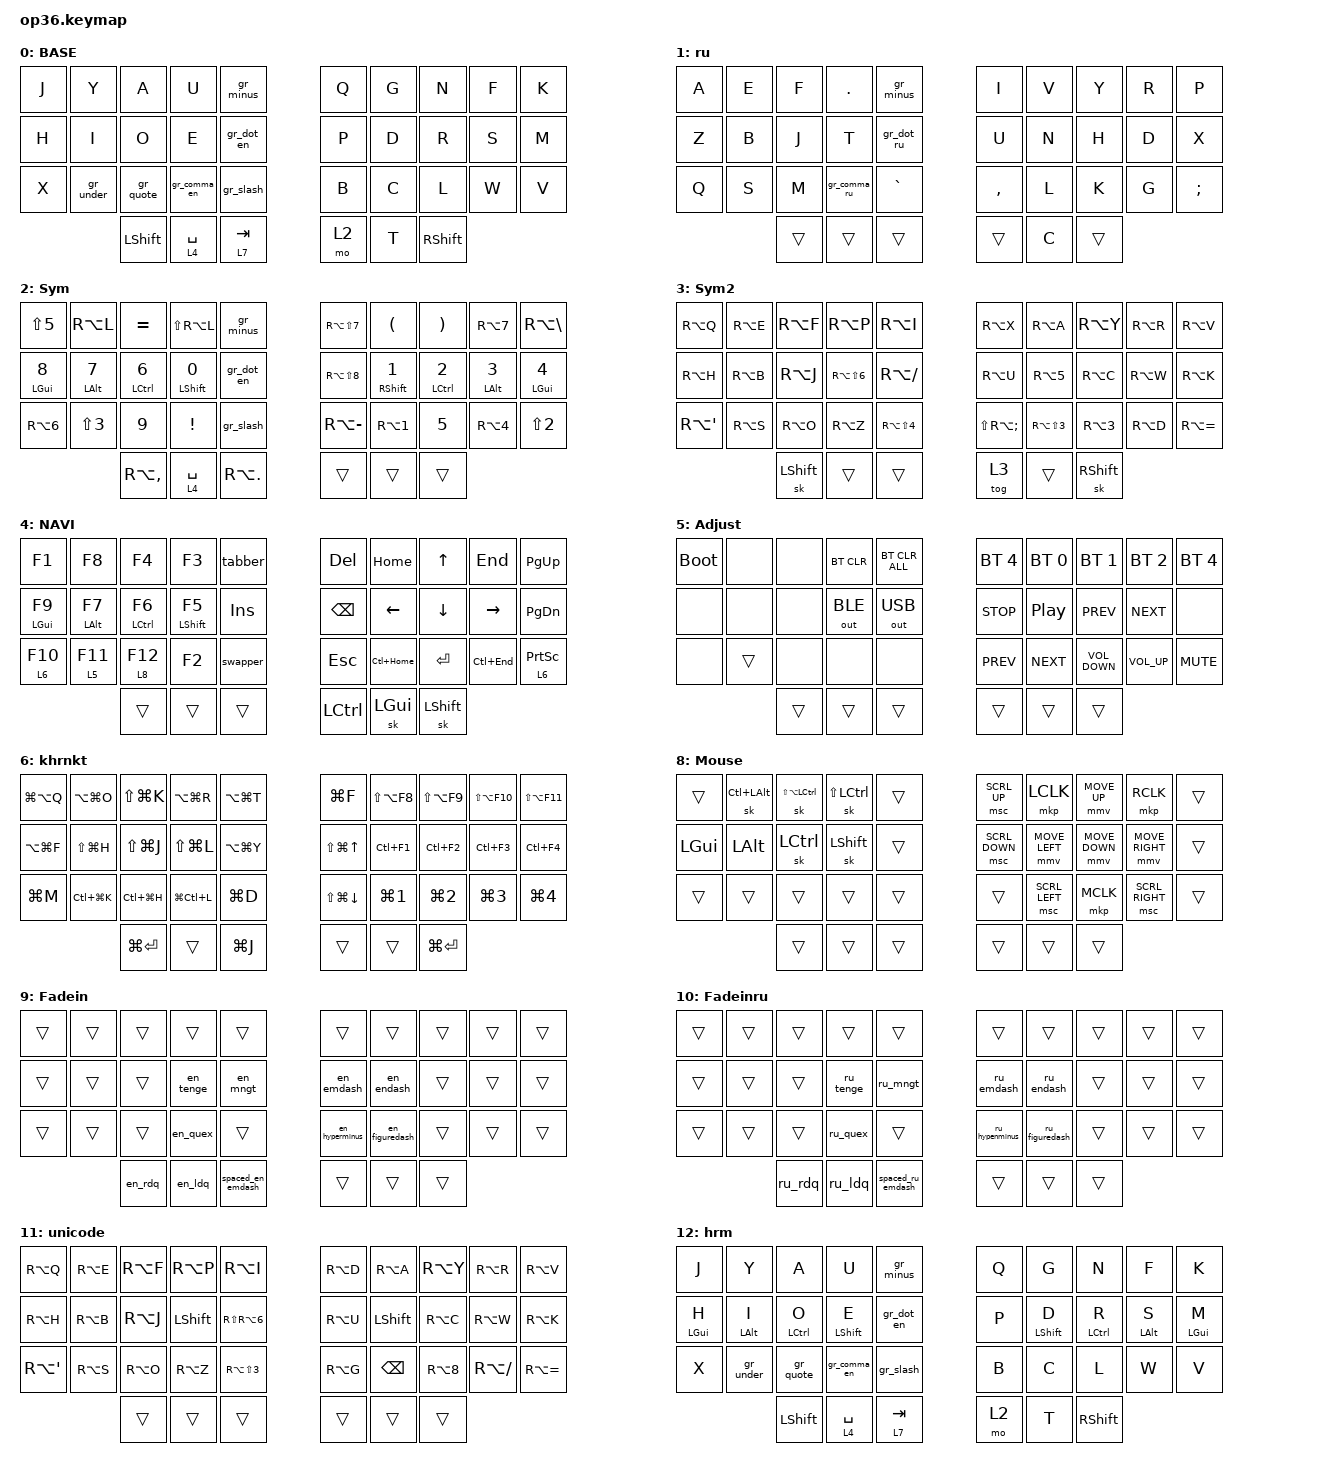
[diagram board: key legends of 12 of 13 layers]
#include "keys_ru.h"
#include <behaviors.dtsi>
#include <dt-bindings/zmk/bt.h>
#include <dt-bindings/zmk/keys.h>
#include <dt-bindings/zmk/outputs.h>
#include <dt-bindings/zmk/pointing.h>

&mt {
    quick-tap-ms = <100>;
    global-quick-tap;
    flavor = "tap-preferred";
    tapping-term-ms = <170>;
};

/ {
    behaviors {
        rus_caps_word: rus_caps_word {
            compatible = "zmk,behavior-russian-capsword";
            #binding-cells = <0>;
            continue-list = <MINUS BACKSPACE DELETE>;
        };

        swapper: swapper {
            compatible = "zmk,behavior-tri-state";
            label = "SWAPPER";
            #binding-cells = <0>;
            bindings = <&kt LALT>, <&kp TAB>, <&kt LALT>;

            ignored-key-positions = <17>, <7>, <35>;
        };

        tabber: tabber {
            compatible = "zmk,behavior-tri-state";
            label = "TABBER";
            #binding-cells = <0>;
            bindings = <&kt LCTL>, <&kp TAB>, <&kt LCTL>;

            ignored-key-positions = <17>, <7>, <35>;
        };

        hml: hrm_left {
            compatible = "zmk,behavior-hold-tap";
            bindings = <&kp>, <&kp>;

            #binding-cells = <2>;
            tapping-term-ms = <170>;
            quick-tap-ms = <125>;
            require-prior-idle-ms = <150>;
            flavor = "balanced";
            hold-trigger-on-release;
            hold-trigger-key-positions = <5 6 7 8 9 31 30 19 18 17 28 16 15 29 27 26 37 36 35>;
        };

        hmr: hrm_right {
            compatible = "zmk,behavior-hold-tap";
            bindings = <&kp>, <&kp>;

            #binding-cells = <2>;
            tapping-term-ms = <170>;
            quick-tap-ms = <125>;
            require-prior-idle-ms = <150>;
            flavor = "balanced";
            hold-trigger-on-release;
            hold-trigger-key-positions = <20 10 22 23 25 24 21 32 33 34 14 13 12 11 0 1 2 3 4>;
        };

        arc_en_left: arc_en_left {
            compatible = "zmk,behavior-adaptive-key";
            #binding-cells = <0>;
            bindings = <&key_repeat>;

            akt_zr {
                trigger-keys = <Z>;
                max-prior-idle-ms = <1000>;
                bindings = <&kp R>;
            };

            akt_jj {
                trigger-keys = <J>;
                max-prior-idle-ms = <1000>;
                bindings = <&kp J>;
            };

            akt_yy {
                trigger-keys = <Y>;
                max-prior-idle-ms = <1000>;
                bindings = <&kp Y>;
            };

            akt_aa {
                trigger-keys = <A>;
                max-prior-idle-ms = <1000>;
                bindings = <&kp A>;
            };

            akt_uu {
                trigger-keys = <U>;
                max-prior-idle-ms = <1000>;
                bindings = <&kp U>;
            };

            akt_mnmn {
                trigger-keys = <MINUS>;
                max-prior-idle-ms = <1000>;
                bindings = <&kp MINUS>;
            };

            akt_lprn {
                trigger-keys = <LPAR>;
                max-prior-idle-ms = <1000>;
                bindings = <&kp LPAR>;
            };

            akt_qu {
                trigger-keys = <Q>;
                max-prior-idle-ms = <1000>;
                bindings = <&kp U>;
            };

            akt_lbrb {
                trigger-keys = <LBKT>;
                max-prior-idle-ms = <1000>;
                bindings = <&kp RBKT>;
            };

            akt_tr {
                trigger-keys = <T>;
                max-prior-idle-ms = <1000>;
                bindings = <&kp R>;
            };

            akt_gh {
                trigger-keys = <G>;
                max-prior-idle-ms = <1000>;
                bindings = <&kp H>;
            };

            akt_nl {
                trigger-keys = <N>;
                max-prior-idle-ms = <1000>;
                bindings = <&kp L>;
            };

            akt_fw {
                trigger-keys = <F>;
                max-prior-idle-ms = <1000>;
                bindings = <&kp W>;
            };

            akt_king {
                trigger-keys = <K>;
                max-prior-idle-ms = <1000>;
                bindings = <&ing>;
            };

            akt_hh {
                trigger-keys = <H>;
                max-prior-idle-ms = <1000>;
                bindings = <&kp H>;
            };

            akt_ii {
                trigger-keys = <I>;
                max-prior-idle-ms = <1000>;
                bindings = <&kp I>;
            };

            akt_oo {
                trigger-keys = <O>;
                max-prior-idle-ms = <1000>;
                bindings = <&kp O>;
            };

            akt_ee {
                trigger-keys = <E>;
                max-prior-idle-ms = <1000>;
                bindings = <&kp E>;
            };

            akt_dotdot {
                trigger-keys = <DOT>;
                max-prior-idle-ms = <1000>;
                bindings = <&kp DOT>;
            };

            akt_scsc {
                trigger-keys = <SEMICOLON>;
                max-prior-idle-ms = <1000>;
                bindings = <&kp SEMICOLON>;
            };

            akt_pb {
                trigger-keys = <P>;
                max-prior-idle-ms = <1000>;
                bindings = <&kp B>;
            };

            akt_dg {
                trigger-keys = <D>;
                max-prior-idle-ms = <1000>;
                bindings = <&kp G>;
            };

            akt_rn {
                trigger-keys = <R>;
                max-prior-idle-ms = <1000>;
                bindings = <&kp N>;
            };

            akt_sw {
                trigger-keys = <S>;
                max-prior-idle-ms = <1000>;
                bindings = <&kp W>;
            };

            akt_mv {
                trigger-keys = <M>;
                max-prior-idle-ms = <1000>;
                bindings = <&kp V>;
            };

            akt_xh {
                trigger-keys = <X>;
                max-prior-idle-ms = <1000>;
                bindings = <&kp H>;
            };

            akt_br {
                trigger-keys = <B>;
                max-prior-idle-ms = <1000>;
                bindings = <&kp R>;
            };

            akt_ck {
                trigger-keys = <C>;
                max-prior-idle-ms = <1000>;
                bindings = <&kp K>;
            };

            akt_ln {
                trigger-keys = <L>;
                max-prior-idle-ms = <1000>;
                bindings = <&kp N>;
            };

            akt_ws {
                trigger-keys = <W>;
                max-prior-idle-ms = <1000>;
                bindings = <&kp S>;
            };

            akt_vm {
                trigger-keys = <V>;
                max-prior-idle-ms = <1000>;
                bindings = <&kp M>;
            };
        };

        arc_ru_left: arc_ru_left {
            compatible = "zmk,behavior-adaptive-key";
            #binding-cells = <0>;
            bindings = <&key_repeat>;

            akt_yaya {
                trigger-keys = <Z>;
                max-prior-idle-ms = <1000>;
                bindings = <&kp Z>;
            };

            akt_gd {
                trigger-keys = <U>;
                max-prior-idle-ms = <1000>;
                bindings = <&kp L>;
            };

            akt_oo {
                trigger-keys = <J>;
                max-prior-idle-ms = <1000>;
                bindings = <&kp J>;
            };

            akt_nr {
                trigger-keys = <Y>;
                max-prior-idle-ms = <1000>;
                bindings = <&kp R>;
            };

            akt_ff {
                trigger-keys = <A>;
                max-prior-idle-ms = <1000>;
                bindings = <&kp A>;
            };

            akt_apap {
                trigger-keys = <APOS>;
                max-prior-idle-ms = <1000>;
                bindings = <&kp APOS>;
            };

            akt_mnmn {
                trigger-keys = <MINUS>;
                max-prior-idle-ms = <1000>;
                bindings = <&kp MINUS>;
            };

            akt_lprn {
                trigger-keys = <LPAR>;
                max-prior-idle-ms = <1000>;
                bindings = <&kp LPRN>;
            };

            akt_yy {
                trigger-keys = <Q>;
                max-prior-idle-ms = <1000>;
                bindings = <&kp Q>;
            };

            akt_khr {
                trigger-keys = <LBKT>;
                max-prior-idle-ms = <1000>;
                bindings = <&kp H>;
            };

            akt_ee {
                trigger-keys = <T>;
                max-prior-idle-ms = <1000>;
                bindings = <&kp T>;
            };

            akt_pn {
                trigger-keys = <G>;
                max-prior-idle-ms = <1000>;
                bindings = <&kp Y>;
            };

            akt_tm {
                trigger-keys = <N>;
                max-prior-idle-ms = <1000>;
                bindings = <&kp V>;
            };

            akt_aa {
                trigger-keys = <F>;
                max-prior-idle-ms = <1000>;
                bindings = <&kp F>;
            };

            akt_ln {
                trigger-keys = <K>;
                max-prior-idle-ms = <1000>;
                bindings = <&kp Y>;
            };

            akt_rn {
                trigger-keys = <H>;
                max-prior-idle-ms = <1000>;
                bindings = <&kp Y>;
            };

            akt_sht {
                trigger-keys = <I>;
                max-prior-idle-ms = <1000>;
                bindings = <&kp N>;
            };

            akt_schn {
                trigger-keys = <O>;
                max-prior-idle-ms = <1000>;
                bindings = <&kp Y>;
            };

            akt_uu {
                trigger-keys = <E>;
                max-prior-idle-ms = <1000>;
                bindings = <&kp E>;
            };

            akt_dotdot {
                trigger-keys = <SLASH>;
                max-prior-idle-ms = <1000>;
                bindings = <&kp SLASH>;
            };

            akt_yuyu {
                trigger-keys = <DOT>;
                max-prior-idle-ms = <1000>;
                bindings = <&kp DOT>;
            };

            akt_zhch {
                trigger-keys = <SEMICOLON>;
                max-prior-idle-ms = <1000>;
                bindings = <&kp X>;
            };

            akt_zzh {
                trigger-keys = <P>;
                max-prior-idle-ms = <1000>;
                bindings = <&kp SEMICOLON>;
            };

            akt_vk {
                trigger-keys = <D>;
                max-prior-idle-ms = <1000>;
                bindings = <&kp R>;
            };

            akt_kp {
                trigger-keys = <R>;
                max-prior-idle-ms = <1000>;
                bindings = <&kp G>;
            };

            akt_yiyi {
                trigger-keys = <S>;
                max-prior-idle-ms = <1000>;
                bindings = <&kp S>;
            };

            akt__ {
                trigger-keys = <M>;
                max-prior-idle-ms = <1000>;
                bindings = <&kp M>;
            };

            akt_chzh {
                trigger-keys = <X>;
                max-prior-idle-ms = <1000>;
                bindings = <&kp SEMICOLON>;
            };

            akt_bsch {
                trigger-keys = <COMMA>;
                max-prior-idle-ms = <1000>;
                bindings = <&kp O>;
            };

            akt_ii {
                trigger-keys = <B>;
                max-prior-idle-ms = <1000>;
                bindings = <&kp B>;
            };

            akt_stv {
                trigger-keys = <C>;
                max-prior-idle-ms = <1000>;
                bindings = <&kp N>;
            };

            akt_dn {
                trigger-keys = <L>;
                max-prior-idle-ms = <1000>;
                bindings = <&kp Y>;
            };

            akt_tzm {
                trigger-keys = <W>;
                max-prior-idle-ms = <1000>;
                bindings = <&kp V>;
            };

            akt_mb {
                trigger-keys = <V>;
                max-prior-idle-ms = <1000>;
                bindings = <&kp COMMA>;
            };
        };

        arc_en_right: arc_en_right {
            compatible = "zmk,behavior-adaptive-key";
            #binding-cells = <0>;
            bindings = <&key_repeat>;

            akt_zz {
                trigger-keys = <Z>;
                max-prior-idle-ms = <1000>;
                bindings = <&kp Z>;
            };

            akt_ju {
                trigger-keys = <J>;
                max-prior-idle-ms = <1000>;
                bindings = <&kp U>;
            };

            akt_yi {
                trigger-keys = <Y>;
                max-prior-idle-ms = <1000>;
                bindings = <&kp I>;
            };

            akt_ao {
                trigger-keys = <A>;
                max-prior-idle-ms = <1000>;
                bindings = <&kp O>;
            };

            akt_ue {
                trigger-keys = <U>;
                max-prior-idle-ms = <1000>;
                bindings = <&kp E>;
            };

            akt_mngt {
                trigger-keys = <MINUS>;
                max-prior-idle-ms = <1000>;
                bindings = <&kp GT>;
            };

            akt_lprn {
                trigger-keys = <LPAR>;
                max-prior-idle-ms = <1000>;
                bindings = <&kp RPAR>;
            };

            akt_qq {
                trigger-keys = <Q>;
                max-prior-idle-ms = <1000>;
                bindings = <&kp Q>;
            };

            akt_lblb {
                trigger-keys = <LBKT>;
                max-prior-idle-ms = <1000>;
                bindings = <&kp LBKT>;
            };

            akt_th {
                trigger-keys = <T>;
                max-prior-idle-ms = <1000>;
                bindings = <&kp H>;
            };

            akt_gg {
                trigger-keys = <G>;
                max-prior-idle-ms = <1000>;
                bindings = <&kp G>;
            };

            akt_nn {
                trigger-keys = <N>;
                max-prior-idle-ms = <1000>;
                bindings = <&kp N>;
            };

            akt_ff {
                trigger-keys = <F>;
                max-prior-idle-ms = <1000>;
                bindings = <&kp F>;
            };

            akt_kk {
                trigger-keys = <K>;
                max-prior-idle-ms = <1000>;
                bindings = <&kp K>;
            };

            akt_hy {
                trigger-keys = <H>;
                max-prior-idle-ms = <1000>;
                bindings = <&kp Y>;
            };

            akt_iy {
                trigger-keys = <I>;
                max-prior-idle-ms = <1000>;
                bindings = <&kp Y>;
            };

            akt_oa {
                trigger-keys = <O>;
                max-prior-idle-ms = <1000>;
                bindings = <&kp A>;
            };

            akt_eu {
                trigger-keys = <E>;
                max-prior-idle-ms = <1000>;
                bindings = <&kp U>;
            };

            akt_dotsp {
                trigger-keys = <DOT>;
                max-prior-idle-ms = <1000>;
                bindings = <&sp_shift>;
            };

            akt_sclp {
                trigger-keys = <SEMICOLON>;
                max-prior-idle-ms = <1000>;
                bindings = <&kp RPAR>;
            };

            akt_pp {
                trigger-keys = <P>;
                max-prior-idle-ms = <1000>;
                bindings = <&kp P>;
            };

            akt_dd {
                trigger-keys = <D>;
                max-prior-idle-ms = <1000>;
                bindings = <&kp D>;
            };

            akt_rr {
                trigger-keys = <R>;
                max-prior-idle-ms = <1000>;
                bindings = <&kp R>;
            };

            akt_ss {
                trigger-keys = <S>;
                max-prior-idle-ms = <1000>;
                bindings = <&kp S>;
            };

            akt_mm {
                trigger-keys = <M>;
                max-prior-idle-ms = <1000>;
                bindings = <&kp M>;
            };

            akt_xh {
                trigger-keys = <X>;
                max-prior-idle-ms = <1000>;
                bindings = <&kp H>;
            };

            akt_bb {
                trigger-keys = <B>;
                max-prior-idle-ms = <1000>;
                bindings = <&kp B>;
            };

            akt_cc {
                trigger-keys = <C>;
                max-prior-idle-ms = <1000>;
                bindings = <&kp C>;
            };

            akt_ll {
                trigger-keys = <L>;
                max-prior-idle-ms = <1000>;
                bindings = <&kp L>;
            };

            akt_ww {
                trigger-keys = <W>;
                max-prior-idle-ms = <1000>;
                bindings = <&kp W>;
            };

            akt_vv {
                trigger-keys = <V>;
                max-prior-idle-ms = <1000>;
                bindings = <&kp V>;
            };
        };

        arc_ru_right: arc_ru_right {
            compatible = "zmk,behavior-adaptive-key";
            #binding-cells = <0>;
            bindings = <&key_repeat>;

            akt_yay {
                trigger-keys = <Z>;
                max-prior-idle-ms = <1000>;
                bindings = <&kp Q>;
            };

            akt_oa {
                trigger-keys = <J>;
                max-prior-idle-ms = <1000>;
                bindings = <&kp F>;
            };

            akt_nn {
                trigger-keys = <Y>;
                max-prior-idle-ms = <1000>;
                bindings = <&kp Y>;
            };

            akt_fya {
                trigger-keys = <A>;
                max-prior-idle-ms = <1000>;
                bindings = <&kp Z>;
            };

            akt_apa {
                trigger-keys = <APOS>;
                max-prior-idle-ms = <1000>;
                bindings = <&kp F>;
            };

            akt_mnsp {
                trigger-keys = <MINUS>;
                max-prior-idle-ms = <1000>;
                bindings = <&kp SPACE>;
            };

            akt_lprn {
                trigger-keys = <LPAR>;
                max-prior-idle-ms = <1000>;
                bindings = <&kp RPAR>;
            };

            akt_yf {
                trigger-keys = <Q>;
                max-prior-idle-ms = <1000>;
                bindings = <&kp A>;
            };

            akt_khkh {
                trigger-keys = <LBKT>;
                max-prior-idle-ms = <1000>;
                bindings = <&kp LBKT>;
            };

            akt_edot {
                trigger-keys = <T>;
                max-prior-idle-ms = <1000>;
                bindings = <&kp SLASH>;
            };

            akt_pp {
                trigger-keys = <G>;
                max-prior-idle-ms = <1000>;
                bindings = <&kp G>;
            };

            akt_tt {
                trigger-keys = <N>;
                max-prior-idle-ms = <1000>;
                bindings = <&kp N>;
            };

            akt_ao {
                trigger-keys = <F>;
                max-prior-idle-ms = <1000>;
                bindings = <&kp J>;
            };

            akt_ll {
                trigger-keys = <K>;
                max-prior-idle-ms = <1000>;
                bindings = <&kp K>;
            };

            akt_rr {
                trigger-keys = <H>;
                max-prior-idle-ms = <1000>;
                bindings = <&kp H>;
            };

            akt_shsh {
                trigger-keys = <I>;
                max-prior-idle-ms = <1000>;
                bindings = <&kp I>;
            };

            akt_schn {
                trigger-keys = <O>;
                max-prior-idle-ms = <1000>;
                bindings = <&kp Y>;
            };

            akt_ui {
                trigger-keys = <E>;
                max-prior-idle-ms = <1000>;
                bindings = <&kp B>;
            };

            akt_dotsp {
                trigger-keys = <SLASH>;
                max-prior-idle-ms = <1000>;
                bindings = <&sp_shift>;
            };

            akt_yuzp {
                trigger-keys = <DOT>;
                max-prior-idle-ms = <1000>;
                bindings = <&comma_sp_ru>;
            };

            akt_zhzh {
                trigger-keys = <SEMICOLON>;
                max-prior-idle-ms = <1000>;
                bindings = <&kp SEMICOLON>;
            };

            akt_zz {
                trigger-keys = <P>;
                max-prior-idle-ms = <1000>;
                bindings = <&kp P>;
            };

            akt_vv {
                trigger-keys = <D>;
                max-prior-idle-ms = <1000>;
                bindings = <&kp D>;
            };

            akt_kk {
                trigger-keys = <R>;
                max-prior-idle-ms = <1000>;
                bindings = <&kp R>;
            };

            akt_yii {
                trigger-keys = <S>;
                max-prior-idle-ms = <1000>;
                bindings = <&kp B>;
            };

            akt__yiyu {
                trigger-keys = <M>;
                max-prior-idle-ms = <1000>;
                bindings = <&kp DOT>;
            };

            akt_chch {
                trigger-keys = <X>;
                max-prior-idle-ms = <1000>;
                bindings = <&kp X>;
            };

            akt_bb {
                trigger-keys = <COMMA>;
                max-prior-idle-ms = <1000>;
                bindings = <&kp COMMA>;
            };

            akt_iu {
                trigger-keys = <B>;
                max-prior-idle-ms = <1000>;
                bindings = <&kp E>;
            };

            akt_stv {
                trigger-keys = <C>;
                max-prior-idle-ms = <1000>;
                bindings = <&kp RBKT>;
            };

            akt_dd {
                trigger-keys = <L>;
                max-prior-idle-ms = <1000>;
                bindings = <&kp L>;
            };

            akt_tztz {
                trigger-keys = <W>;
                max-prior-idle-ms = <1000>;
                bindings = <&kp W>;
            };

            akt_mm {
                trigger-keys = <V>;
                max-prior-idle-ms = <1000>;
                bindings = <&kp V>;
            };
        };

        arcane_left_en: arcane_left_en {
            compatible = "zmk,behavior-hold-tap";
            label = "ARCANE_LEFT_EN";
            bindings = <&kp>, <&arc_en_left>;

            #binding-cells = <2>;
            tapping-term-ms = <200>;
            flavor = "hold-preferred";
        };

        arcane_left_ru: arcane_left_ru {
            compatible = "zmk,behavior-hold-tap";
            label = "ARCANE_LEFT_RU";
            bindings = <&kp>, <&arc_ru_left>;

            #binding-cells = <2>;
            tapping-term-ms = <200>;
            flavor = "hold-preferred";
        };

        arcane_right_en: arcane_right_en {
            compatible = "zmk,behavior-hold-tap";
            label = "ARCANE_RIGHT_EN";
            bindings = <&kp>, <&arc_en_right>;

            #binding-cells = <2>;
            tapping-term-ms = <200>;
            flavor = "hold-preferred";
        };

        arcane_right_ru: arcane_right_ru {
            compatible = "zmk,behavior-hold-tap";
            label = "ARCANE_RIGHT_RU";
            bindings = <&kp>, <&arc_ru_right>;

            #binding-cells = <2>;
            tapping-term-ms = <200>;
            flavor = "hold-preferred";
        };

        layer_sft: layer_sft {
            compatible = "zmk,behavior-hold-tap";
            label = "LAYER_SFT";
            bindings = <&mo>, <&sk>;

            #binding-cells = <2>;
            tapping-term-ms = <200>;
        };

        gr_dot_en: gr_dot_en {
            compatible = "zmk,behavior-mod-morph";
            label = "GR_DOT_EN";
            bindings = <&kp RA(LS(C))>, <&kp RA(LS(NUMBER_2))>;

            #binding-cells = <0>;
            mods = <(MOD_LSFT|MOD_RSFT)>;
        };

        gr_dot_ru: gr_dot_ru {
            compatible = "zmk,behavior-mod-morph";
            label = "GR_DOT_RU";
            bindings = <&kp SLASH>, <&kp RA(LS(NUMBER_2))>;

            #binding-cells = <0>;
            mods = <(MOD_LSFT|MOD_RSFT)>;
        };

        gr_comma_en: gr_comma_en {
            compatible = "zmk,behavior-mod-morph";
            label = "GR_COMMA_EN";
            bindings = <&gm_commaspace_en>, <&kp RA(LS(N5))>;

            #binding-cells = <0>;
            mods = <(MOD_LSFT|MOD_RSFT)>;
        };

        gr_comma_ru: gr_comma_ru {
            compatible = "zmk,behavior-mod-morph";
            label = "GR_COMMA_RU";
            bindings = <&gm_commaspace_ru>, <&kp RA(LS(N5))>;

            #binding-cells = <0>;
            mods = <(MOD_LSFT|MOD_RSFT)>;
        };

        gr_minus: gr_minus {
            compatible = "zmk,behavior-mod-morph";
            label = "GR_MINUS";
            bindings = <&kp MINUS>, <&kp KP_PLUS>;

            #binding-cells = <0>;
            mods = <(MOD_LSFT|MOD_RSFT)>;
        };

        gr_slash: gr_slash {
            compatible = "zmk,behavior-mod-morph";
            label = "GR_SLASH";
            bindings = <&kp RA(LS(BACKSLASH))>, <&kp ASTERISK>;

            #binding-cells = <0>;
            mods = <(MOD_LSFT|MOD_RSFT)>;
        };

        gr_quote: gr_quote {
            compatible = "zmk,behavior-mod-morph";
            label = "GR_QUOTE";
            bindings = <&kp RA(NUMBER_2)>, <&kp RA(GRAVE)>;

            #binding-cells = <0>;
            mods = <(MOD_LSFT|MOD_RSFT)>;
        };

        gr_under: gr_under {
            compatible = "zmk,behavior-mod-morph";
            label = "GR_UNDER";
            bindings = <&kp UNDERSCORE>, <&kp BSLH>;

            #binding-cells = <0>;
            mods = <(MOD_LSFT|MOD_RSFT)>;
        };

        gr_sqp: gr_sqp {
            compatible = "zmk,behavior-mod-morph";
            label = "GR_SQP";
            bindings = <&kp RA(LEFT_BRACKET)>, <&kp RA(RIGHT_BRACKET)>;

            #binding-cells = <0>;
            mods = <(MOD_LSFT|MOD_RSFT)>;
        };

        line_down_ctrl: line_down_ctrl {
            compatible = "zmk,behavior-hold-tap";
            label = "LINE_DOWN_CTRL";
            bindings = <&kp>, <&new_line_down>;

            #binding-cells = <2>;
            flavor = "balanced";
            tapping-term-ms = <170>;
            quick-tap-ms = <125>;
            require-prior-idle-ms = <150>;
        };

        cut_string_alt: cut_string_alt {
            compatible = "zmk,behavior-hold-tap";
            label = "CUT_STRING_ALT";
            bindings = <&kp>, <&cut_string>;

            #binding-cells = <2>;
            tapping-term-ms = <170>;
            quick-tap-ms = <125>;
            require-prior-idle-ms = <150>;
            flavor = "balanced";
        };

        smc_comma: smc_comma {
            compatible = "zmk,behavior-mod-morph";
            label = "SMC_COMMA";
            bindings = <&kp RA(LS(N8))>, <&kp RA(LS(NUMBER_5))>;

            #binding-cells = <0>;
            mods = <(MOD_LSFT|MOD_RSFT)>;
        };

        sl2_locky: sl2_locky {
            compatible = "zmk,behavior-tap-dance";
            label = "SL2_LOCKY";
            #binding-cells = <0>;
            bindings = <&sl 2>, <&tog 2>;

            tapping-term-ms = <300>;
        };

        sl3_locky: sl3_locky {
            compatible = "zmk,behavior-tap-dance";
            label = "SL3_LOCKY";
            #binding-cells = <0>;
            bindings = <&sl 3>, <&tog 3>;

            tapping-term-ms = <300>;
        };
    };

    combos {
        compatible = "zmk,combos";

        kha {
            bindings = <&kp RA(LBKT)>;
            key-positions = <6 7>;
            layers = <0 3 2>;
        };

        hrdsgn {
            bindings = <&kp RA(RBKT)>;
            key-positions = <7 8>;
            layers = <0 3 2>;
        };

        TO_RU {
            bindings = <&KB_RU>;
            key-positions = <27 28>;
            layers = <0>;
        };

        TO_EN {
            bindings = <&KB_EN>;
            key-positions = <27 28>;
            layers = <1>;
        };

        z {
            bindings = <&kp Z>;
            key-positions = <16 17>;
            layers = <0>;
        };

        undr {
            bindings = <&gr_under>;
            key-positions = <13 14>;
            layers = <1>;
        };

        rusinch {
            bindings = <&gr_quote>;
            key-positions = <7 8>;
            layers = <1>;
        };

        to_sym2 {
            bindings = <&mo 3>;
            key-positions = <31 30>;
            layers = <0 1 2>;
        };

        th_gui {
            bindings = <&sk LEFT_GUI>;
            key-positions = <31 32>;
            layers = <0 1 3>;
        };

        en_lbr {
            bindings = <&kp LEFT_BRACE>;
            key-positions = <16 6>;
            layers = <0 3 2>;
        };

        en_rbr {
            bindings = <&kp RIGHT_BRACE>;
            key-positions = <17 7>;
            layers = <0 3 2>;
        };

        ru_rbrc {
            bindings = <&kp RA(LEFT_BRACKET)>;
            key-positions = <17 7>;
            layers = <1>;
        };

        ru_lbrc {
            bindings = <&kp RA(RIGHT_BRACKET)>;
            key-positions = <16 6>;
            layers = <1>;
        };

        ru_tz {
            bindings = <&kp W>;
            key-positions = <16 17>;
            layers = <1>;
        };

        ru_sl {
            bindings = <&gr_slash>;
            key-positions = <23 24>;
            layers = <1>;
        };

        c_s {
            bindings = <&kp LC(S)>;
            key-positions = <13 12>;
        };

        c_c {
            bindings = <&kp LC(C)>;
            key-positions = <13 3>;
        };

        c_x {
            bindings = <&kp LC(X)>;
            key-positions = <14 4>;
        };

        c_v {
            bindings = <&kp LC(V)>;
            key-positions = <12 2>;
        };

        kh {
            bindings = <&kp LEFT_BRACKET>;
            key-positions = <6 7>;
            layers = <1>;
        };

        c_z {
            bindings = <&kp LC(Z)>;
            key-positions = <23 22>;
        };

        cs_z {
            bindings = <&kp LS(LC(Z))>;
            key-positions = <22 21>;
        };

        rth_ctrl {
            bindings = <&kp LCTRL>;
            key-positions = <33 34>;
            layers = <0 1 4>;
        };

        rth_alt {
            bindings = <&kp LALT>;
            key-positions = <35 34>;
            layers = <0 1 4>;
        };

        ye {
            bindings = <&kp SQT>;
            key-positions = <3 2>;
            layers = <1 0>;
        };

        ru_sch {
            bindings = <&kp RIGHT_BRACKET>;
            key-positions = <17 18>;
            layers = <1>;
        };

        ru_sch2 {
            bindings = <&kp O>;
            key-positions = <26 27>;
            layers = <1>;
        };

        mrck2 {
            bindings = <&mkp RCLK>;
            key-positions = <23 13>;
        };

        mmck {
            bindings = <&mkp MCLK>;
            key-positions = <22 12>;
        };

        mlcck {
            bindings = <&mkp LCLK>;
            key-positions = <24 13>;
        };

        CtrlEnter {
            bindings = <&kp LC(ENTER)>;
            key-positions = <26 26 27 28>;
            layers = <4>;
        };

        Ralt1 {
            bindings = <&kp RALT>;
            key-positions = <24 14>;
        };

        Ralt2 {
            bindings = <&kp RALT>;
            key-positions = <25 15>;
        };

        not_equal {
            bindings = <&not_equal_macro>;
            key-positions = <5 15>;
        };

        fadein_en {
            bindings = <&sl 9>;
            key-positions = <25 26>;
            layers = <0>;
        };

        fadein_ru {
            bindings = <&sl 10>;
            key-positions = <25 26>;
        };

        ShiftEnter {
            bindings = <&kp LC(ENTER)>;
            key-positions = <26 27>;
            layers = <4>;
        };

        cpswrd {
            bindings = <&caps_word>;
            key-positions = <32 33>;
            layers = <0>;
        };

        cpswrd_ru {
            bindings = <&rus_caps_word>;
            key-positions = <32 33>;
            layers = <1>;
        };

        paste_text {
            bindings = <&kp LS(LC(LA(V)))>;
            key-positions = <2 12>;
            layers = <7>;
        };

        m23 {
            bindings = <&p23>;
            key-positions = <17 18>;
            layers = <2>;
        };

        ctrl-up {
            bindings = <&kp LC(UP)>;
            key-positions = <7 17>;
            layers = <4>;
        };

        ctrl-down {
            bindings = <&kp LC(DOWN)>;
            key-positions = <17 27>;
            layers = <4>;
        };

        ctrl-left {
            bindings = <&kp LC(LEFT)>;
            key-positions = <16 17>;
            layers = <4>;
        };

        ctrl-right {
            bindings = <&kp LC(RIGHT_ARROW)>;
            key-positions = <17 18>;
            layers = <4>;
        };

        ctrl-bksp {
            bindings = <&kp LC(BACKSPACE)>;
            key-positions = <15 16>;
            layers = <4>;
        };

        to_adj_l {
            bindings = <&mo 5>;
            key-positions = <10 11>;
        };

        to_adj_r {
            bindings = <&mo 5>;
            key-positions = <18 19>;
        };

        sym_astr {
            bindings = <&kp ASTRK>;
            key-positions = <16 17>;
            layers = <2>;
        };

        sym_tilde {
            bindings = <&kp RA(LS(GRAVE))>;
            key-positions = <15 16>;
            layers = <2>;
        };

        sym_bslsh {
            bindings = <&kp BSLH>;
            key-positions = <26 27>;
            layers = <2>;
        };

        sym_plus {
            bindings = <&kp PLUS>;
            key-positions = <2 3>;
            layers = <2>;
        };

        sym_comma {
            bindings = <&kp RA(LS(NUMBER_5))>;
            key-positions = <12 13>;
            layers = <2>;
        };

        sym_gr {
            bindings = <&kp RA(GRAVE)>;
            key-positions = <13 14>;
            layers = <2>;
        };

        to_app_5 {
            bindings = <&kp LG(NUMBER_5)>;
            key-positions = <26 27>;
            layers = <6>;
        };

        to_app_6 {
            bindings = <&kp LG(N6)>;
            key-positions = <27 28>;
            layers = <6>;
        };

        to_table_5 {
            bindings = <&kp LC(F15)>;
            key-positions = <16 17>;
            layers = <6>;
        };

        to_table_6 {
            bindings = <&kp LC(F16)>;
            key-positions = <17 18>;
            layers = <6>;
        };

        onto_table_5 {
            bindings = <&kp LA(LS(F15))>;
            key-positions = <6 7>;
            layers = <6>;
        };

        onto_table_6 {
            bindings = <&kp LA(LS(F16))>;
            key-positions = <7 8>;
            layers = <6>;
        };

        to_app_8 {
            bindings = <&kp LG(N8)>;
            key-positions = <26 27 28 29>;
            layers = <6>;
        };

        to_table_7 {
            bindings = <&kp LC(F17)>;
            key-positions = <17 18 16>;
            layers = <6>;
        };

        to_table_8 {
            bindings = <&kp LC(F18)>;
            key-positions = <17 18 16 19>;
            layers = <6>;
        };

        onto_table_7 {
            bindings = <&kp LA(LS(F17))>;
            key-positions = <7 8 6>;
            layers = <6>;
        };

        onto_table_8 {
            bindings = <&kp LA(LS(F18))>;
            key-positions = <7 8 6 9>;
            layers = <6>;
        };
    };

    macros {
        KB_EN: KB_EN {
            compatible = "zmk,behavior-macro";
            #binding-cells = <0>;
            bindings =
                <&kp LC(LA(NUMBER_6))>,
                <&macro_wait_time 25>,
                <&to 0>,
                <&macro_wait_time 25>;

            label = "KB_EN";
        };

        KB_RU: KB_RU {
            compatible = "zmk,behavior-macro";
            #binding-cells = <0>;
            bindings =
                <&kp LC(LA(N7))>,
                <&macro_wait_time 25>,
                <&to 1>,
                <&macro_wait_time 25>;

            label = "KB_RU";
        };

        gm_commaspace_en: dotspace_en {
            compatible = "zmk,behavior-macro";
            #binding-cells = <0>;
            bindings = <&kp COMMA &kp SPACE>;
            label = "DOTSPACE_EN";
        };

        gm_commaspace_ru: dotspace_ru {
            compatible = "zmk,behavior-macro";
            #binding-cells = <0>;
            bindings = <&kp QUESTION &kp SPACE>;
            label = "DOTSPACE_RU";
        };

        ru_emdash: ru_emdash {
            compatible = "zmk,behavior-macro";
            #binding-cells = <0>;
            bindings =
                <&KB_EN>,
                <&macro_wait_time 30>,
                <&kp LS(LC(U))>,
                <&macro_wait_time 10>,
                <&kp N2 &kp N0 &kp N1 &kp N4 &kp ENTER>,
                <&macro_wait_time 30>,
                <&KB_RU>;

            label = "RU_EMDASH";
        };

        en_emdash: en_emdash {
            compatible = "zmk,behavior-macro";
            #binding-cells = <0>;
            bindings =
                <&kp LS(LC(U))>,
                <&macro_wait_time 10>,
                <&kp N2 &kp N0 &kp N1 &kp N4 &kp ENTER>,
                <&macro_wait_time 10>;

            label = "EN_EMDASH";
        };

        en_rdq: en_rdq {
            compatible = "zmk,behavior-macro";
            #binding-cells = <0>;
            bindings =
                <&kp LS(LC(U))>,
                <&macro_wait_time 10>,
                <&kp N0 &kp N0 &kp B &kp B &kp ENTER>,
                <&macro_wait_time 10>;

            label = "EN_RDQ";
        };

        ru_ldq: ru_ldq {
            compatible = "zmk,behavior-macro";
            #binding-cells = <0>;
            bindings =
                <&KB_EN>,
                <&macro_wait_time 10>,
                <&kp LS(LC(U))>,
                <&macro_wait_time 10>,
                <&kp N0 &kp N0 &kp A &kp B &kp ENTER>,
                <&macro_wait_time 10>,
                <&KB_RU>;

            label = "RU_LDQ";
        };

        ru_rdq: ru_rdq {
            compatible = "zmk,behavior-macro";
            #binding-cells = <0>;
            bindings =
                <&KB_EN>,
                <&macro_wait_time 10>,
                <&kp LS(LC(U))>,
                <&macro_wait_time 10>,
                <&kp N0 &kp N0 &kp B &kp B &kp ENTER>,
                <&macro_wait_time 10>,
                <&KB_RU>;

            label = "RU_RDQ";
        };

        en_ldq: en_ldq {
            compatible = "zmk,behavior-macro";
            #binding-cells = <0>;
            bindings =
                <&kp LS(LC(U))>,
                <&macro_wait_time 10>,
                <&kp N0 &kp N0 &kp A &kp B &kp ENTER>,
                <&macro_wait_time 10>;

            label = "EN_LDQ";
        };

        ru_lbr: ru_lbr {
            compatible = "zmk,behavior-macro";
            #binding-cells = <0>;
            bindings =
                <&KB_EN>,
                <&macro_wait_time 10>,
                <&kp LEFT_BRACE>,
                <&macro_wait_time 10>,
                <&KB_RU>;

            label = "RU_LBR";
        };

        ru_rbr: ru_rbr {
            compatible = "zmk,behavior-macro";
            #binding-cells = <0>;
            bindings =
                <&KB_EN>,
                <&macro_wait_time 10>,
                <&kp RIGHT_BRACE>,
                <&macro_wait_time 10>,
                <&KB_RU>;

            label = "RU_RBR";
        };

        en_endash: en_endash {
            compatible = "zmk,behavior-macro";
            #binding-cells = <0>;
            bindings =
                <&kp LS(LC(U))>,
                <&macro_wait_time 10>,
                <&kp NUMBER_2 &kp NUMBER_0 &kp N1 &kp NUMBER_3 &kp ENTER>,
                <&macro_wait_time 10>;

            label = "EN_ENDASH";
        };

        ru_endash: ru_endash {
            compatible = "zmk,behavior-macro";
            #binding-cells = <0>;
            bindings =
                <&KB_EN>,
                <&macro_wait_time 10>,
                <&kp LS(LC(U))>,
                <&macro_wait_time 10>,
                <&kp NUMBER_2 &kp NUMBER_0 &kp N1 &kp NUMBER_3 &kp ENTER>,
                <&macro_wait_time 10>,
                <&KB_RU>;

            label = "RU_ENDASH";
        };

        new_line_down: new_line_down {
            compatible = "zmk,behavior-macro";
            #binding-cells = <0>;
            bindings = <&kp END>, <&macro_wait_time 0>, <&kp LS(ENTER)>;

            label = "NEW_LINE_DOWN";
        };

        new_line_up: new_line_up {
            compatible = "zmk,behavior-macro";
            #binding-cells = <0>;
            bindings = <&kp HOME>, <&macro_wait_time 0>, <&kp LS(ENTER)>;

            label = "NEW_LINE_UP";
        };

        cut_string: cut_string {
            compatible = "zmk,behavior-macro";
            #binding-cells = <0>;
            bindings =
                <&kp HOME>,
                <&macro_wait_time 0>,
                <&kp LS(DOWN)>,
                <&macro_wait_time 0>,
                <&kp LC(X)>;

            label = "CUT_STRING";
        };

        copy_string: copy_string {
            compatible = "zmk,behavior-macro";
            #binding-cells = <0>;
            bindings =
                <&kp HOME>,
                <&macro_wait_time 0>,
                <&kp LS(DOWN)>,
                <&macro_wait_time 0>,
                <&kp LC(C)>;

            label = "COPY_STRING";
        };

        sp_shift: sp_shift {
            compatible = "zmk,behavior-macro";
            #binding-cells = <0>;
            bindings = <&kp SPACE>, <&macro_wait_time 5>, <&sk LEFT_SHIFT>;

            label = "SP_SHIFT";
        };

        comma_sp_ru: comma_sp_ru {
            compatible = "zmk,behavior-macro";
            #binding-cells = <0>;
            bindings = <&kp QUESTION>, <&macro_wait_time 5>, <&kp SPACE>;

            label = "COMMA_SPACE_RU";
        };

        ing: ing {
            compatible = "zmk,behavior-macro";
            #binding-cells = <0>;
            bindings = <&kp I &kp N &kp G>;
            label = "ING";
        };

        ru_hypenminus: ru_hypenminus {
            compatible = "zmk,behavior-macro";
            #binding-cells = <0>;
            bindings =
                <&KB_EN>,
                <&macro_wait_time 30>,
                <&kp LS(LC(U))>,
                <&macro_wait_time 10>,
                <&kp N0 &kp N0 &kp NUMBER_2 &kp D &kp ENTER>,
                <&macro_wait_time 30>,
                <&KB_RU>;

            label = "RU_HYPENMINUS";
        };

        en_hyperminus: en_hyperminus {
            compatible = "zmk,behavior-macro";
            #binding-cells = <0>;
            bindings =
                <&kp LS(LC(U))>,
                <&macro_wait_time 10>,
                <&kp N0 &kp N0 &kp NUMBER_2 &kp D &kp ENTER>,
                <&macro_wait_time 30>;

            label = "EN_HYPERMINUS";
        };

        ru_figuredash: ru_figuredash {
            compatible = "zmk,behavior-macro";
            #binding-cells = <0>;
            bindings =
                <&KB_EN>,
                <&macro_wait_time 30>,
                <&kp LS(LC(U))>,
                <&macro_wait_time 10>,
                <&kp NUMBER_2 &kp N0 &kp NUMBER_1 &kp NUMBER_2 &kp ENTER>,
                <&macro_wait_time 30>,
                <&KB_RU>;

            label = "RU_FIGUREDASH";
        };

        en_figuredash: en_figuredash {
            compatible = "zmk,behavior-macro";
            #binding-cells = <0>;
            bindings =
                <&kp LS(LC(U))>,
                <&macro_wait_time 10>,
                <&kp NUMBER_2 &kp N0 &kp NUMBER_1 &kp NUMBER_2 &kp ENTER>,
                <&macro_wait_time 30>;

            label = "EN_FIGUREDASH";
        };

        ru_tenge: ru_tenge {
            compatible = "zmk,behavior-macro";
            #binding-cells = <0>;
            bindings =
                <&KB_EN>,
                <&macro_wait_time 30>,
                <&kp LS(LC(U))>,
                <&macro_wait_time 10>,
                <&kp NUMBER_2 &kp N0 &kp B &kp N8 &kp ENTER>,
                <&macro_wait_time 30>,
                <&KB_RU>;

            label = "RU_TENGE";
        };

        en_tenge: en_tenge {
            compatible = "zmk,behavior-macro";
            #binding-cells = <0>;
            bindings =
                <&kp LS(LC(U))>,
                <&macro_wait_time 10>,
                <&kp NUMBER_2 &kp N0 &kp B &kp N8 &kp ENTER>,
                <&macro_wait_time 30>;

            label = "EN_TENGE";
        };

        ru_mngt: ru_mngt {
            compatible = "zmk,behavior-macro";
            #binding-cells = <0>;
            bindings =
                <&KB_EN>,
                <&macro_wait_time 30>,
                <&kp LS(LC(U))>,
                <&macro_wait_time 10>,
                <&kp NUMBER_2 &kp N0 &kp NUMBER_2 &kp NUMBER_6 &kp ENTER>,
                <&macro_wait_time 30>,
                <&KB_RU>;

            label = "RU_MNGT";
        };

        en_mngt: en_mngt {
            compatible = "zmk,behavior-macro";
            #binding-cells = <0>;
            bindings =
                <&kp LS(LC(U))>,
                <&macro_wait_time 10>,
                <&kp NUMBER_2 &kp N0 &kp NUMBER_2 &kp NUMBER_6 &kp ENTER>,
                <&macro_wait_time 30>;

            label = "EN_MNGT";
        };

        ru_quex: ru_quex {
            compatible = "zmk,behavior-macro";
            #binding-cells = <0>;
            bindings =
                <&KB_EN>,
                <&macro_wait_time 30>,
                <&kp LS(LC(U))>,
                <&macro_wait_time 10>,
                <&kp NUMBER_2 &kp N0 &kp NUMBER_4 &kp N8 &kp ENTER>,
                <&macro_wait_time 30>,
                <&KB_RU>;

            label = "RU_QUEX";
        };

        en_quex: en_quex {
            compatible = "zmk,behavior-macro";
            #binding-cells = <0>;
            bindings =
                <&kp LS(LC(U))>,
                <&macro_wait_time 10>,
                <&kp NUMBER_2 &kp N0 &kp NUMBER_4 &kp N8 &kp ENTER>,
                <&macro_wait_time 30>;

            label = "EN_QUEX";
        };

        not_equal_macro: not_equal {
            compatible = "zmk,behavior-macro";
            #binding-cells = <0>;
            bindings = <&kp EXCL &kp EQUAL>;
            label = "NOT_EQUAL";
        };

        emdash_spaced: emdash_spaced {
            compatible = "zmk,behavior-macro";
            #binding-cells = <0>;
            bindings = <&kp SPACE &kp RA(MINUS) &kp SPACE>;
            label = "EMDASH_SPACED";
        };

        spaced_ru_emdash: spaced_ru_emdash {
            compatible = "zmk,behavior-macro";
            #binding-cells = <0>;
            bindings =
                <&KB_EN>,
                <&macro_wait_time 50>,
                <&kp SPACE>,
                <&macro_wait_time 5>,
                <&kp LS(LC(U))>,
                <&macro_wait_time 10>,
                <&kp N2 &kp N0 &kp N1 &kp N4 &kp ENTER>,
                <&macro_wait_time 30>,
                <&KB_RU>,
                <&macro_wait_time 5>,
                <&kp SPACE>;

            label = "SPACED_RU_EMDASH";
        };

        spaced_en_emdash: spaced_en_emdash {
            compatible = "zmk,behavior-macro";
            #binding-cells = <0>;
            bindings =
                <&kp SPACE>,
                <&macro_wait_time 10>,
                <&kp LS(LC(U))>,
                <&macro_wait_time 10>,
                <&kp N2 &kp N0 &kp N1 &kp N4 &kp ENTER>,
                <&macro_wait_time 10>,
                <&kp SPACE>;

            label = "SPACED_EN_EMDASH";
        };

        gm_dot_space_shift: gm_dot_space_shift {
            compatible = "zmk,behavior-macro";
            #binding-cells = <0>;
            bindings = <&kp RA(LS(C)) &kp SPACE &sk LSHFT>;
            label = "GM_DOT_SPACE_SHIFT";
        };

        arr_left: arr_left {
            compatible = "zmk,behavior-macro";
            #binding-cells = <0>;
            bindings = <&kp RA(L) &kp MINUS>;
            label = "ARR_LEFT";
        };

        arr_right: arr_right {
            compatible = "zmk,behavior-macro";
            #binding-cells = <0>;
            bindings = <&kp MINUS &kp RA(LS(L))>;
            label = "ARR_RIGHT";
        };

        tag_close: tag_close {
            compatible = "zmk,behavior-macro";
            #binding-cells = <0>;
            bindings = <&kp RA(L) &kp RA(LS(BACKSLASH))>;
            label = "TAG_CLOSE";
        };

        p23: p23 {
            compatible = "zmk,behavior-macro";
            #binding-cells = <0>;
            bindings = <&kp PRCNT &kp N2 &kp N3>;
            label = "P23";
        };
    };

    keymap {
        compatible = "zmk,keymap";

        en_base {
            label = "BASE";
            bindings = <
  &kp J  &kp Y      &kp A      &kp U         &gr_minus                        &kp Q  &kp G      &kp N  &kp F  &kp K
  &kp H  &kp I      &kp O      &kp E         &gr_dot_en                       &kp P  &kp D      &kp R  &kp S  &kp M
  &kp X  &gr_under  &gr_quote  &gr_comma_en  &gr_slash                        &kp B  &kp C      &kp L  &kp W  &kp V
                               &kp LSHFT     &lt 4 SPACE  &lt 7 TAB    &mo 2  &kp T  &kp RSHFT
            >;
        };

        ru {
            bindings = <
  &kp A  &kp E  &kp F  &kp DOT       &gr_minus                     &kp I      &kp V   &kp Y  &kp R  &kp P
  &kp Z  &kp B  &kp J  &kp T         &gr_dot_ru                    &kp U      &kp N   &kp H  &kp D  &kp X
  &kp Q  &kp S  &kp M  &gr_comma_ru  &kp GRAVE                     &kp COMMA  &kp L   &kp K  &kp G  &kp SEMICOLON
                       &trans        &trans      &trans    &trans  &kp C      &trans
            >;
        };

        Sym {
            label = "Sym";
            bindings = <
  &kp LS(N5)        &kp RA(L)         &kp EQUAL      &kp LS(RA(L))  &gr_minus                           &kp RA(LS(N7))  &kp LPAR             &kp RPAR             &kp RA(N7)          &kp RA(BSLH)
  &hml LEFT_GUI N8  &hml LALT N7      &hml LCTRL N6  &hml LSHFT N0  &gr_dot_en                          &kp RA(LS(N8))  &hmr RSHFT NUMBER_1  &hmr LCTRL NUMBER_2  &hmr LALT NUMBER_3  &hmr LEFT_GUI NUMBER_4
  &kp RA(N6)        &kp LS(NUMBER_3)  &kp N9         &kp EXCL       &gr_slash                           &kp RA(MINUS)   &kp RA(N1)           &kp N5               &kp RA(NUMBER_4)    &kp LS(NUMBER_2)
                                                     &kp RA(COMMA)  &lt 4 SPACE  &kp RA(DOT)    &trans  &trans          &trans
            >;
        };

        Sym2 {
            bindings = <
  &kp RA(Q)    &kp RA(E)  &kp RA(F)  &kp RA(P)       &kp RA(I)                               &kp RA(X)         &kp RA(A)             &kp RA(Y)         &kp RA(R)  &kp RA(V)
  &kp RA(H)    &kp RA(B)  &kp RA(J)  &kp RA(LS(N6))  &kp RA(SLASH)                           &kp RA(U)         &kp RA(NUMBER_5)      &kp RA(C)         &kp RA(W)  &kp RA(K)
  &kp RA(SQT)  &kp RA(S)  &kp RA(O)  &kp RA(Z)       &kp RA(LS(NUMBER_4))                    &kp LS(RA(SEMI))  &kp RA(LS(NUMBER_3))  &kp RA(NUMBER_3)  &kp RA(D)  &kp RA(EQUAL)
                                     &sk LSHFT       &trans                &trans    &tog 3  &trans            &sk RSHFT
            >;
        };

        nav_layer {
            label = "NAVI";
            bindings = <
  &kp F1        &kp F8        &kp F4         &kp F3         &tabber                        &kp DELETE     &kp HOME        &kp UP_ARROW    &kp END          &kp PAGE_UP
  &hml LGUI F9  &hml LALT F7  &hml LCTRL F6  &hml LSHFT F5  &kp INS                        &kp BACKSPACE  &kp LEFT_ARROW  &kp DOWN_ARROW  &kp RIGHT_ARROW  &kp PG_DN
  &lt 6 F10     &lt 5 F11     &lt 8 F12      &kp F2         &swapper                       &kp ESC        &kp LC(HOME)    &kp ENTER       &kp LC(END)      &lt 6 PRINTSCREEN
                                             &trans         &trans    &trans    &kp LCTRL  &sk LEFT_GUI   &sk LSHFT
            >;
        };

        adj {
            label = "adj";
            bindings = <
  &bootloader  &none   &none  &bt BT_CLR    &bt BT_CLR_ALL                    &bt BT_SEL 4  &bt BT_SEL 0      &bt BT_SEL 1       &bt BT_SEL 2     &bt BT_SEL 4
  &none        &none   &none  &out OUT_BLE  &out OUT_USB                      &kp C_STOP    &kp C_PLAY_PAUSE  &kp C_PREV         &kp C_NEXT       &none
  &none        &trans  &none  &none         &none                             &kp C_PREV    &kp C_NEXT        &kp C_VOLUME_DOWN  &kp C_VOLUME_UP  &kp C_MUTE
                              &trans        &trans          &trans    &trans  &trans        &trans
            >;

            display-name = "Adjust";
        };

        khronkite {
            label = "khrnkt";
            bindings = <
  &kp LG(LA(Q))  &kp LA(LG(O))  &kp LS(LG(K))  &kp LA(LG(R))  &kp LA(LG(T))                       &kp LG(F)             &kp LS(LA(F8))  &kp LS(LA(F9))    &kp LS(LA(F10))   &kp LS(LA(F11))
  &kp LA(LG(F))  &kp LS(LG(H))  &kp LS(LG(J))  &kp LS(LG(L))  &kp LA(LG(Y))                       &kp LS(LG(UP_ARROW))  &kp LC(F1)      &kp LC(F2)        &kp LC(F3)        &kp LC(F4)
  &kp LG(M)      &kp LC(LG(K))  &kp LC(LG(H))  &kp LG(LC(L))  &kp LG(D)                           &kp LS(LG(DOWN))      &kp LG(N1)      &kp LG(NUMBER_2)  &kp LG(NUMBER_3)  &kp LG(NUMBER_4)
                                               &kp LG(ENTER)  &trans         &kp LG(J)    &trans  &trans                &kp LG(ENTER)
            >;
        };

        Shortcuts {
            bindings = <
  &kp LS(DEL)    &kp LC(W)  &kp LC(LS(I))  &kp LS(LC(R))  &kp LC(T)                    &kp LC(MINUS)  &kp LC(D)      &kp LC(N)          &kp LS(LC(M))  &kp LC(COMMA)
  &kp LS(LC(K))  &kp LC(L)  &kp LC(S)      &kp LC(A)      &kp LC(F)                    &kp LC(EQUAL)  &kp LC(P)      &kp LS(LA(LC(E)))  &kp LC(O)      &kp LC(DOT)
  &kp LA(F8)     &kp LA(Z)  &kp LC(G)      &kp LC(R)      &kp LC(H)                    &kp LC(B)      &kp LC(I)      &kp LC(U)          &kp LS(LC(X))  &kp LC(Q)
                                           &trans         &trans     &trans    &mo 12  &kp LC(LS(C))  &kp LC(LS(V))
            >;
        };

        Mouse {
            bindings = <
  &trans        &sk LC(LALT)  &sk LS(LA(LCTRL))  &sk LS(LCTRL)  &trans                    &msc SCRL_UP    &mkp LCLK       &mmv MOVE_UP    &mkp RCLK        &trans
  &kp LEFT_GUI  &kp LALT      &sk LCTRL          &sk LSHFT      &trans                    &msc SCRL_DOWN  &mmv MOVE_LEFT  &mmv MOVE_DOWN  &mmv MOVE_RIGHT  &trans
  &trans        &trans        &trans             &trans         &trans                    &trans          &msc SCRL_LEFT  &mkp MCLK       &msc SCRL_RIGHT  &trans
                                                 &trans         &trans  &trans    &trans  &trans          &trans
            >;
        };

        Fadein {
            bindings = <
  &trans  &trans  &trans  &trans     &trans                                 &trans          &trans          &trans  &trans  &trans
  &trans  &trans  &trans  &en_tenge  &en_mngt                               &en_emdash      &en_endash      &trans  &trans  &trans
  &trans  &trans  &trans  &en_quex   &trans                                 &en_hyperminus  &en_figuredash  &trans  &trans  &trans
                          &en_rdq    &en_ldq   &spaced_en_emdash    &trans  &trans          &trans
            >;
        };

        Fadeinru {
            bindings = <
  &trans  &trans  &trans  &trans     &trans                                 &trans          &trans          &trans  &trans  &trans
  &trans  &trans  &trans  &ru_tenge  &ru_mngt                               &ru_emdash      &ru_endash      &trans  &trans  &trans
  &trans  &trans  &trans  &ru_quex   &trans                                 &ru_hypenminus  &ru_figuredash  &trans  &trans  &trans
                          &ru_rdq    &ru_ldq   &spaced_ru_emdash    &trans  &trans          &trans
            >;
        };

        unicode {
            bindings = <
  &kp RA(Q)    &kp RA(E)  &kp RA(F)  &kp RA(P)  &kp RA(I)                               &kp RA(D)  &kp RA(A)  &kp RA(Y)         &kp RA(R)      &kp RA(V)
  &kp RA(H)    &kp RA(B)  &kp RA(J)  &kp LSHFT  &kp RS(RA(NUMBER_6))                    &kp RA(U)  &kp LSHFT  &kp RA(C)         &kp RA(W)      &kp RA(K)
  &kp RA(SQT)  &kp RA(S)  &kp RA(O)  &kp RA(Z)  &kp RA(LS(NUMBER_3))                    &kp RA(G)  &kp BSPC   &kp RA(NUMBER_8)  &kp RA(SLASH)  &kp RA(EQUAL)
                                     &trans     &trans                &trans    &trans  &trans     &trans
            >;
        };

        layer_12 {
            label = "hrm";
            bindings = <
  &kp J            &kp Y            &kp A         &kp U         &gr_minus                        &kp Q  &kp G         &kp N         &kp F        &kp K
  &hml LEFT_GUI H  &hml LEFT_ALT I  &hml LCTRL O  &hml LSHFT E  &gr_dot_en                       &kp P  &hmr LSHFT D  &hmr LCTRL R  &hmr LALT S  &hmr LGUI M
  &kp X            &gr_under        &gr_quote     &gr_comma_en  &gr_slash                        &kp B  &kp C         &kp L         &kp W        &kp V
                                                  &kp LSHFT     &lt 4 SPACE  &lt 7 TAB    &mo 2  &kp T  &kp RSHFT
            >;
        };
    };
};
